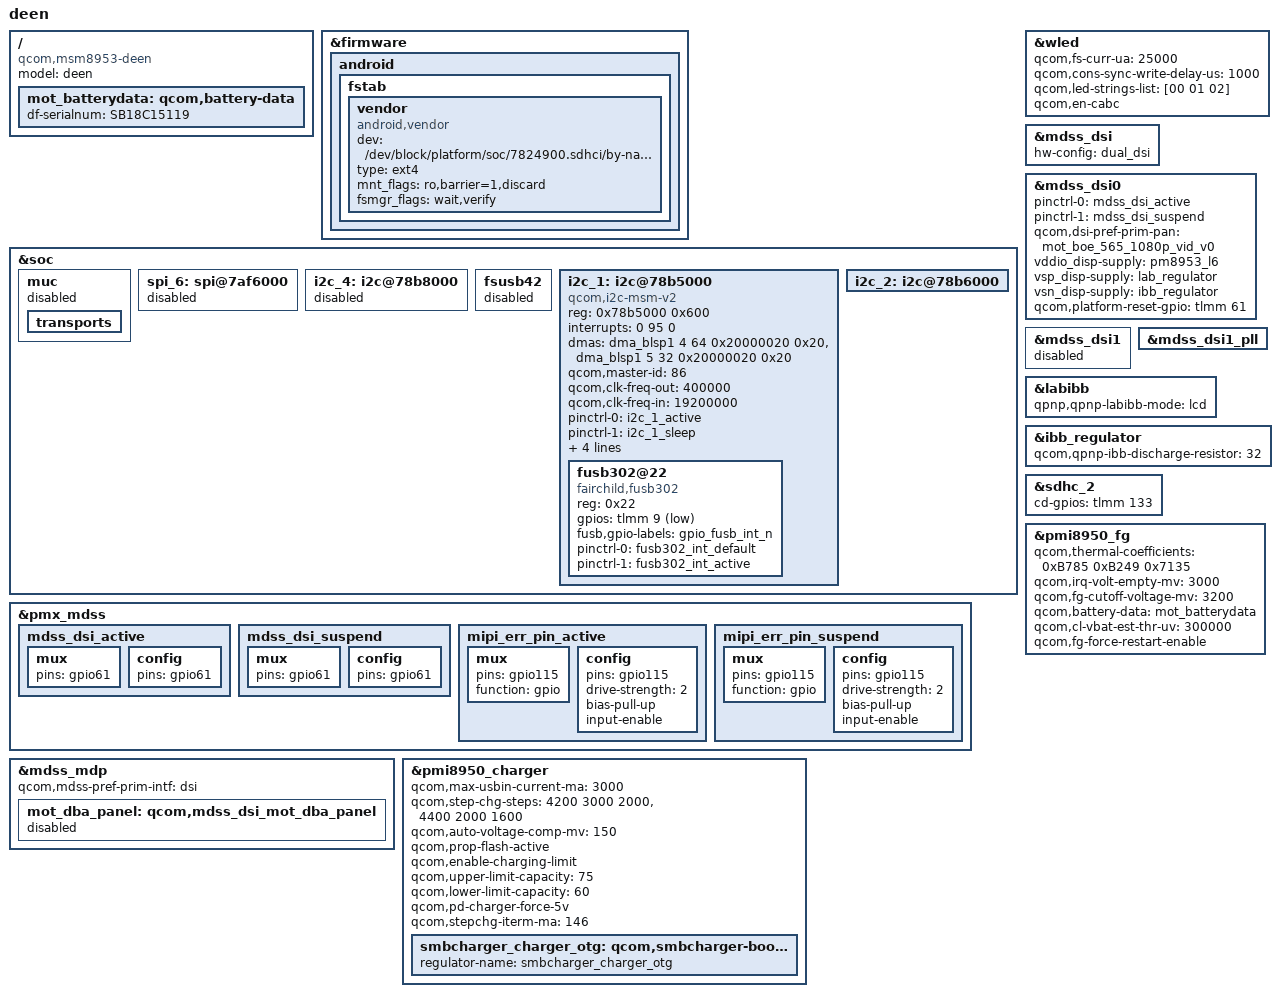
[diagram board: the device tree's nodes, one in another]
/* Copyright (c) 2018, Motorola Mobility Inc. All rights reserved.
 *
 * This program is free software; you can redistribute it and/or modify
 * it under the terms of the GNU General Public License version 2 and
 * only version 2 as published by the Free Software Foundation.
 *
 * This program is distributed in the hope that it will be useful,
 * but WITHOUT ANY WARRANTY; without even the implied warranty of
 * MERCHANTABILITY or FITNESS FOR A PARTICULAR PURPOSE.  See the
 * GNU General Public License for more details.
 */

#include "msm8953-moto-common.dtsi"
#include "dsi-panel-mot-boe-565-1080p-vid.dtsi"
#include "dsi-panel-mot-tianma-565-1080p-vid.dtsi"
#include "sdm450-deen-pinctrl.dtsi"

 / {
	model = "deen";
	compatible = "qcom,msm8953-deen", "qcom,msm8953-moto",
			"qcom,msm8953";
};

&firmware {
	android {
		fstab {
			vendor {
				compatible = "android,vendor";
				dev = "/dev/block/platform/soc/7824900.sdhci/by-name/vendor";
				type = "ext4";
				mnt_flags = "ro,barrier=1,discard";
				fsmgr_flags = "wait,verify";
				status = "ok";
			};
		};
	};
};

&soc {

	muc: muc {
		status = "disabled";
		transports {
			/delete-node/ i2c@78b5000;
		};
	};
	spi_6: spi@7af6000 { /* BLSP2 QUP2 */
		status = "disabled";
	};

	i2c_4: i2c@78b8000 {
		status = "disabled";
		/delete-node/ motosh@43;
	};

	fsusb42 {
		status = "disabled";
	};

	i2c_1: i2c@78b5000 {
		compatible = "qcom,i2c-msm-v2";
		#address-cells = <1>;
		#size-cells = <0>;
		reg-names = "qup_phys_addr";
		reg = <0x78b5000 0x600>;
		interrupt-names = "qup_irq";
		interrupts = <0 95 0>;
		dmas = <&dma_blsp1 4 64 0x20000020 0x20>,
			<&dma_blsp1 5 32 0x20000020 0x20>;
		dma-names = "tx", "rx";
		qcom,master-id = <86>;
		qcom,clk-freq-out = <400000>;
		qcom,clk-freq-in  = <19200000>;
		pinctrl-names = "i2c_active", "i2c_sleep";
		pinctrl-0 = <&i2c_1_active>;
		pinctrl-1 = <&i2c_1_sleep>;
		qcom,noise-rjct-scl = <0>;
		qcom,noise-rjct-sda = <0>;
		clock-names = "iface_clk", "core_clk";
		clocks = <&clock_gcc clk_gcc_blsp1_ahb_clk>,
			 <&clock_gcc clk_gcc_blsp1_qup1_i2c_apps_clk>;

		fusb302@22 {
			compatible = "fairchild,fusb302";
			reg = <0x22>;
			gpios = <&tlmm 9 1>; /* FUSB302_INT_N, in */
			fusb,gpio-labels = "gpio_fusb_int_n";
			pinctrl-names = "default", "active";
			pinctrl-0 = <&fusb302_int_default>;
			pinctrl-1 = <&fusb302_int_active>;
		};
	};

	i2c_2: i2c@78b6000 { /* BLSP1 QUP2 */
		/delete-node/ fusb302@22;
	};
};

&wled {
	qcom,fs-curr-ua = <25000>;
	qcom,cons-sync-write-delay-us = <1000>;
	qcom,led-strings-list = [00 01 02];
	qcom,en-cabc;
};

&pmx_mdss {
	mdss_dsi_active {
		mux {
			pins = "gpio61";
		};

		config {
			pins = "gpio61";
		};
	};

	mdss_dsi_suspend {
		mux {
			pins = "gpio61";
		};

		config {
			pins = "gpio61";
		};
	};

	mipi_err_pin_active: mipi_err_pin_active {
		mux {
			pins = "gpio115";
			function = "gpio";
		};

		config {
			pins = "gpio115";
			drive-strength = <2>; /* 2 mA */
			bias-pull-up; /* pull up */
			input-enable;
		};
	};

	mipi_err_pin_suspend: mipi_err_pin_suspend {
		mux {
			pins = "gpio115";
			function = "gpio";
		};

		config {
			pins = "gpio115";
			drive-strength = <2>; /* 2 mA */
			bias-pull-up; /* pull up */
			input-enable;
		};
	};
};

&mdss_mdp {
	qcom,mdss-pref-prim-intf = "dsi";

	mot_dba_panel: qcom,mdss_dsi_mot_dba_panel{
		#include "dsi-panel-mot-mod-fwvga-video-common.dtsi"
	};
};

&mdss_dsi {
	hw-config = "dual_dsi";
};

&mdss_dsi0 {
	pinctrl-names = "mdss_default", "mdss_sleep";
	pinctrl-0 = <&mdss_dsi_active>;
	pinctrl-1 = <&mdss_dsi_suspend>;

	qcom,dsi-pref-prim-pan = <&mot_boe_565_1080p_vid_v0>;

	/delete-property/ vdd-supply;
	vddio_disp-supply = <&pm8953_l6>;
	vsp_disp-supply = <&lab_regulator>;
	vsn_disp-supply = <&ibb_regulator>;

	qcom,platform-reset-gpio = <&tlmm 61 0>;
};

&mdss_dsi1 {
	status = "disabled";
};

&mdss_dsi1_pll {
	/delete-property/ qcom,dsi-pll-ssc-en;
	/delete-property/ qcom,dsi-pll-ssc-mode;
};

&mot_dba_panel {
	status = "disabled";
};


/* display boost and inverting boost regulators */
&labibb {
	status = "ok";
	qpnp,qpnp-labibb-mode = "lcd";
};

&ibb_regulator {
	qcom,qpnp-ibb-discharge-resistor = <32>;
};

&sdhc_2 {
	cd-gpios = <&tlmm 133 0x0>;
};

&pmi8950_charger {
	/delete-property/ pinctrl-names;
	/delete-property/ pinctrl-0;
	/delete-property/ gpios;
	/delete-property/ gpio-names;

	qcom,max-usbin-current-ma = <3000>;
	qcom,step-chg-steps = <4200 3000 2000>,
				<4400 2000 1600>;
	qcom,auto-voltage-comp-mv = <150>;
	qcom,prop-flash-active;
	qcom,enable-charging-limit;
	qcom,upper-limit-capacity = <75>;
	qcom,lower-limit-capacity = <60>;
	qcom,pd-charger-force-5v;
	qcom,stepchg-iterm-ma = <146>;

	smbcharger_charger_otg: qcom,smbcharger-boost-otg {
		status = "okay";
		regulator-name = "smbcharger_charger_otg";
	};
};

/{
	/delete-node/ qcom,battery-data;
	mot_batterydata: qcom,battery-data {
		df-serialnum = "SB18C15119";
		#include "batterydata-hg30-atl-ali.dtsi"
		#include "batterydata-hg30-scud.dtsi"
	};
};

&pmi8950_fg {
	/delete-property/ qcom,battery-data;
	qcom,thermal-coefficients =  /bits/ 16 <0xB785 0xB249 0x7135>;
	qcom,irq-volt-empty-mv = <3000>;
	qcom,fg-cutoff-voltage-mv = <3200>;
	qcom,battery-data = <&mot_batterydata>;
	qcom,cl-vbat-est-thr-uv = <300000>;
	qcom,fg-force-restart-enable;
};
